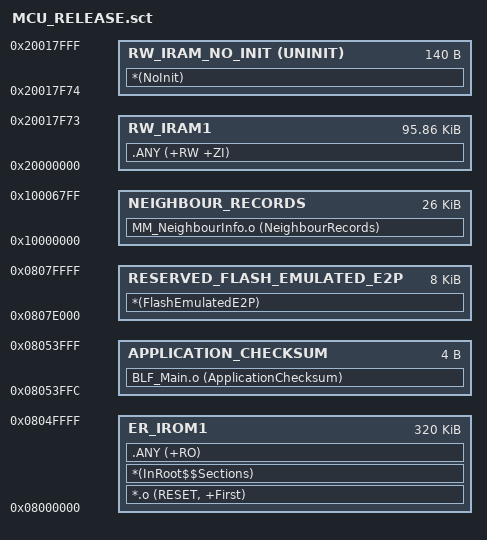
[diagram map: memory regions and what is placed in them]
; *************************************************************
; *** Scatter-Loading Description File generated by uVision ***
; *************************************************************

; Bank 1 Definition
LR_IROM1 0x08000000 (0x0007C000)  {    ; load region size_region

  ER_IROM1 0x08000000 0x00050000 { ; code region
   *.o (RESET, +First)
   *(InRoot$$Sections)
   .ANY (+RO)
  }
  
  ; Reserved area for the Flash Emulated EEPROM
  RESERVED_FLASH_EMULATED_E2P 0x0807e000 8192 {
  *(FlashEmulatedE2P)
  }
  
  ; Reserved area for the application CRC
  APPLICATION_CHECKSUM 0x08053FFC 4 {
   BLF_Main.o (ApplicationChecksum) 
  }
  
  RW_IRAM1 0x20000000 (0x00018000-140) {  ; RW data
   .ANY (+RW +ZI)
  }

  RW_IRAM_NO_INIT (0x20000000+0x00018000-140) UNINIT 140  { ;no init section
    *(NoInit)
  }

  ; Reserved area for the neighbour information records 512x44 bytes
  NEIGHBOUR_RECORDS 0x10000000 26624 {
   MM_NeighbourInfo.o (NeighbourRecords) 
  }
}
